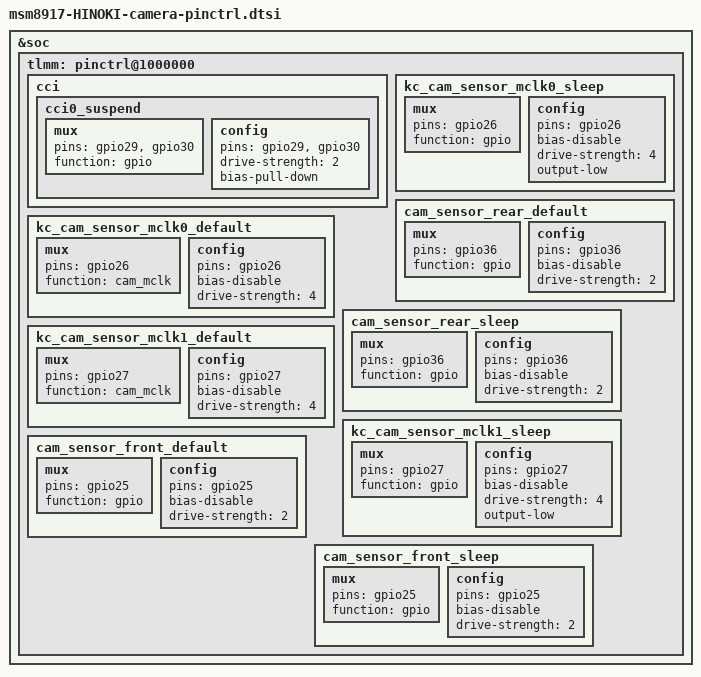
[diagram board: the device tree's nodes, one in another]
/*
 * Copyright (c) 2015, 2018, The Linux Foundation. All rights reserved.
 *
 * This program is free software; you can redistribute it and/or modify
 * it under the terms of the GNU General Public License version 2 and
 * only version 2 as published by the Free Software Foundation.
 *
 * This program is distributed in the hope that it will be useful,
 * but WITHOUT ANY WARRANTY; without even the implied warranty of
 * MERCHANTABILITY or FITNESS FOR A PARTICULAR PURPOSE.  See the
 * GNU General Public License for more details.
 */

&soc {
	tlmm: pinctrl@1000000 {

		/delete-node/ cam_sensor_mclk0_default;
		/delete-node/ cam_sensor_mclk0_sleep;
		/delete-node/ cam_sensor_mclk1_default;
		/delete-node/ cam_sensor_mclk1_sleep;

		cci {
			cci0_suspend: cci0_suspend {
				/* cci0 suspended state */
				mux {
					/* CLK, DATA */
					pins = "gpio29", "gpio30";
					function = "gpio";
				};

				config {
					pins = "gpio29", "gpio30";
					drive-strength = <2>; /* 2 MA */
					bias-pull-down; /* PULL DOWN */
				};
			};
		};

		/*sensors */
		kc_cam_sensor_mclk0_default: kc_cam_sensor_mclk0_default {
			/* MCLK0 */
			mux {
				/* CLK, DATA */
				pins = "gpio26";
				function = "cam_mclk";
			};

			config {
				pins = "gpio26";
				bias-disable; /* No PULL */
				drive-strength = <4>; /* 4 MA */
			};
		};

		kc_cam_sensor_mclk0_sleep: kc_cam_sensor_mclk0_sleep {
			/* MCLK0 */
			mux {
				/* CLK, DATA */
				pins = "gpio26";
				function = "gpio";
			};

			config {
				pins = "gpio26";
				bias-disable; /* No PULL */
				drive-strength = <4>; /* 4 MA */
				output-low;
			};
		};

		cam_sensor_rear_default: cam_sensor_rear_default {
			/* RESET */
			mux {
				pins = "gpio36";
				function = "gpio";
			};

			config {
				pins = "gpio36";
				bias-disable; /* No PULL */
				drive-strength = <2>; /* 2 MA */
			};
		};

		cam_sensor_rear_sleep: cam_sensor_rear_sleep {
			/* RESET */
			mux {
				pins = "gpio36";
				function = "gpio";
			};

			config {
				pins = "gpio36";
				bias-disable; /* No PULL */
				drive-strength = <2>; /* 2 MA */
			};
		};

		kc_cam_sensor_mclk1_default: kc_cam_sensor_mclk1_default {
			/* MCLK1 */
			mux {
				/* CLK, DATA */
				pins = "gpio27";
				function = "cam_mclk";
			};

			config {
				pins = "gpio27";
				bias-disable; /* No PULL */
				drive-strength = <4>; /* 4 MA */
			};
		};

		kc_cam_sensor_mclk1_sleep: kc_cam_sensor_mclk1_sleep {
			/* MCLK1 */
			mux {
				/* CLK, DATA */
				pins = "gpio27";
				function = "gpio";
			};

			config {
				pins = "gpio27";
				bias-disable; /* No PULL */
				drive-strength = <4>; /* 4 MA */
				output-low;
			};
		};

		cam_sensor_front_default: cam_sensor_front_default {
			/* RESET */
			mux {
				pins = "gpio25";
				function = "gpio";
			};

			config {
				pins = "gpio25";
				bias-disable; /* No PULL */
				drive-strength = <2>; /* 2 MA */
			};
		};

		cam_sensor_front_sleep: cam_sensor_front_sleep {
			/* RESET */
			mux {
				pins = "gpio25";
				function = "gpio";
			};

			config {
				pins = "gpio25";
				bias-disable; /* No PULL */
				drive-strength = <2>; /* 2 MA */
			};
		};
	};
};
